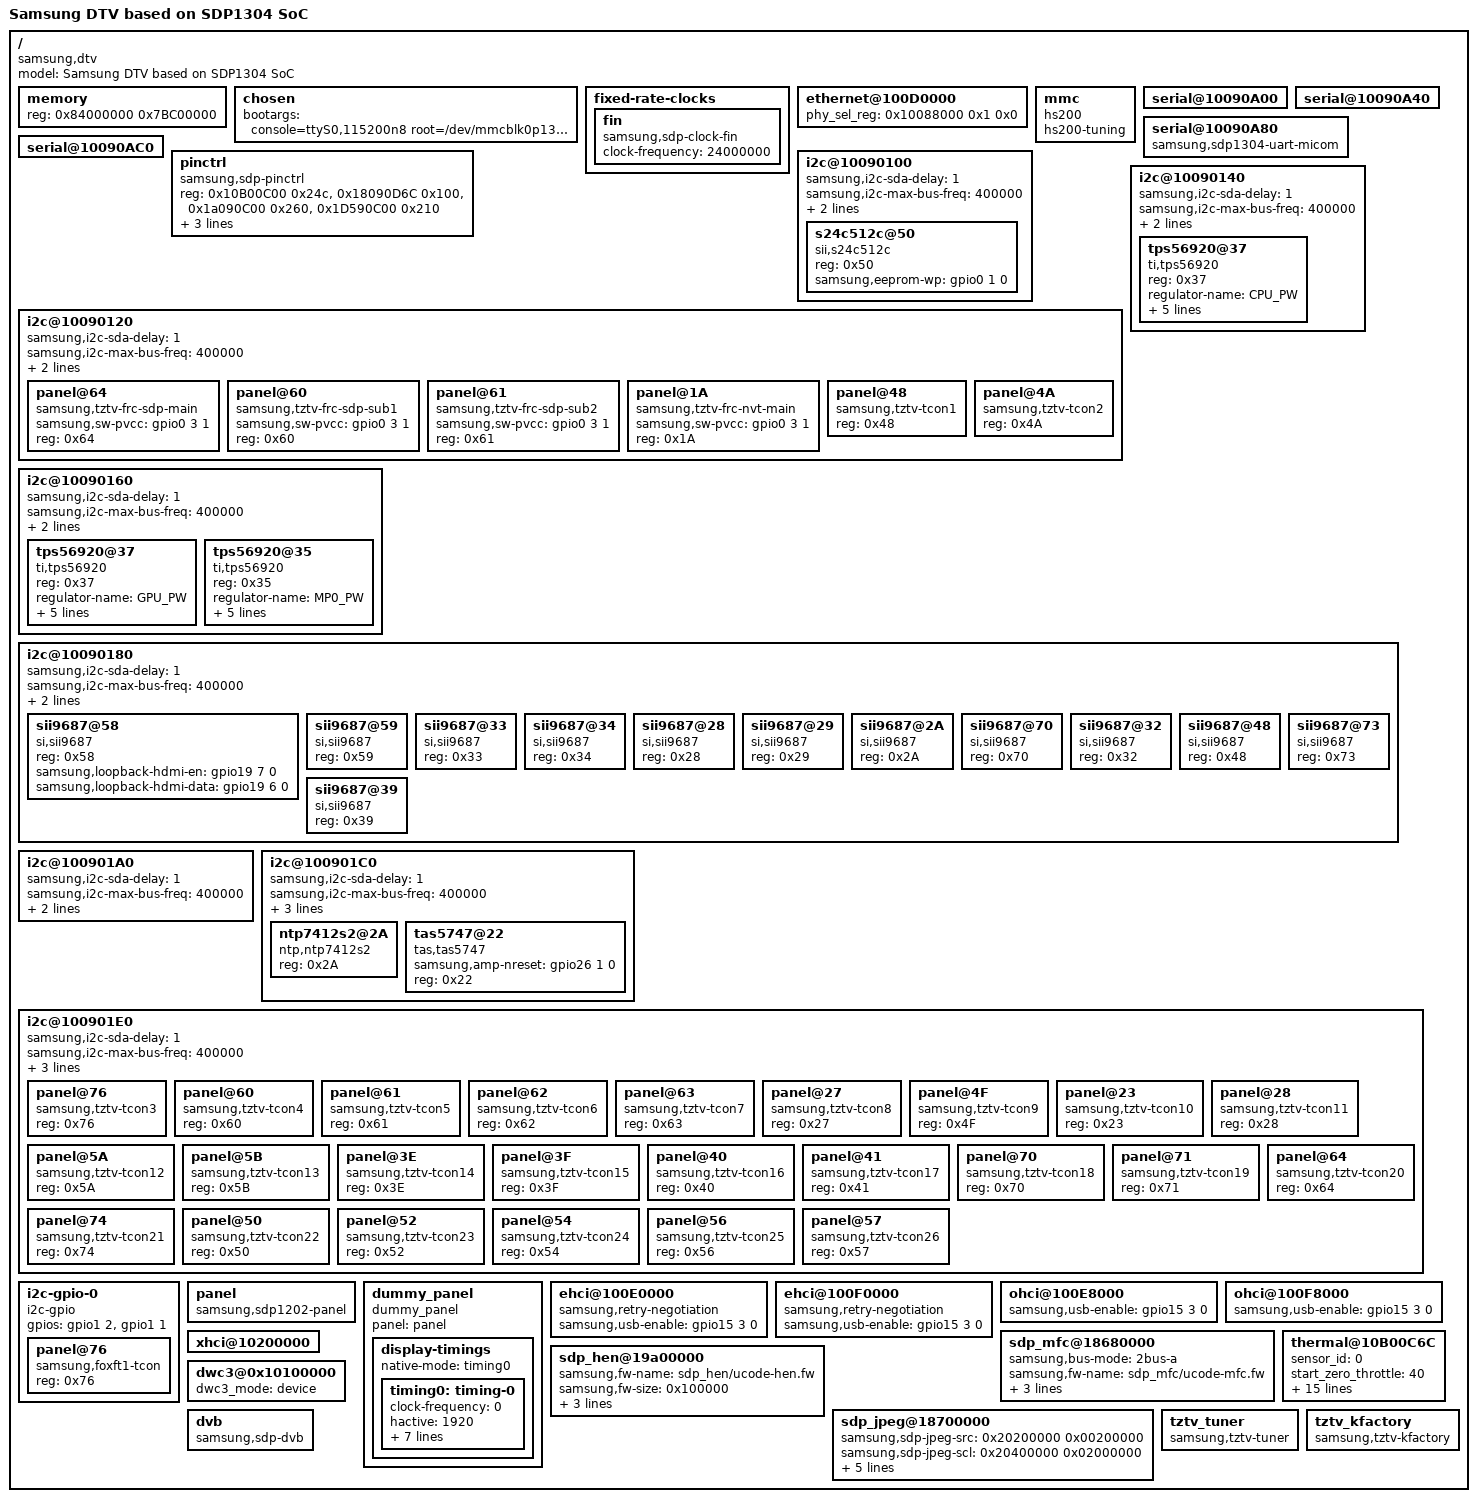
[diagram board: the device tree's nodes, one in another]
/*
 * Copyright (C) 2013 Samsung Electronics Co.Ltd
 *
 * This program is free software; you can redistribute it and/or modify
 * it under the terms of the GNU General Public License version 2 as
 * published by the Free Software Foundation.
 */

/dts-v1/;
#include "sdp1304.dtsi"

/ {
	model = "Samsung DTV based on SDP1304 SoC";
	compatible = "samsung,dtv", "samsung,sdp1304";

        memory {
                reg =  <0x84000000 0x7BC00000>;
        };

        chosen {
                bootargs = "console=ttyS0,115200n8 root=/dev/mmcblk0p13 rootfstype=ext4 rw rootwait earlyprintk no_console_suspend EME_BUFFINFO=0x83F00000,256K vmalloc=400M maintv sdp_sparsemem";
        };

	fixed-rate-clocks {
		fin {
			compatible = "samsung,sdp-clock-fin";
			clock-frequency = <24000000>;
		};
	};

	ethernet@100D0000 {
		phy_sel_reg = <0x10088000 0x1 0x0>;		/* select RGMII for eval board*/
	};

	mmc {
		hs200;/* enable HS200 */
		hs200-tuning;
	};

	serial@10090A00 {
		status = "okay";
	};

	serial@10090A40 {
		status = "okay";
	};

	serial@10090A80 {
		compatible = "samsung,sdp1304-uart-micom";
		status = "okay";
	};

	serial@10090AC0 {
		status = "okay";
	}; 

	pinctrl{
		compatible = "samsung,sdp-pinctrl";
		reg = <0x10B00C00 0x24c>,
			<0x18090D6C 0x100>,
			 <0x1a090C00 0x260>,
			 <0x1D590C00 0x210>;
			 
		start-offset = <0x98 0x0 0x16c 0x1a4>;
		nr-banks = <15 20 20 6>;	
		model-sel = <1 1 0 0>;	
	};

	i2c@10090100 {
		status = "okay";
		samsung,i2c-sda-delay = <1>;
		samsung,i2c-max-bus-freq = <400000>;
		samsung,i2c-irq-status-reg = <0x100901F4>;
		samsung,i2c-cpu-affinity = <3>;

                s24c512c@50 {
			compatible = "sii,s24c512c";
			reg = <0x50>;
			samsung,eeprom-wp = <&gpio0 1 0>;
                };
	};

	i2c@10090120 {
		status = "okay";
		samsung,i2c-sda-delay = <1>;
		samsung,i2c-max-bus-freq = <400000>;
		samsung,i2c-irq-status-reg = <0x100901F4>;
		samsung,i2c-cpu-affinity = <3>;

		/* panel C8 */
		panel@64 {
			compatible = "samsung,tztv-frc-sdp-main";
			samsung,sw-pvcc = <&gpio0 3 1>;
			reg = <0x64>;
		};

		/* panel C0 SUB */
		panel@60 {
			compatible = "samsung,tztv-frc-sdp-sub1";
			samsung,sw-pvcc = <&gpio0 3 1>;
			reg = <0x60>;
		};

		/* panel C2 SUB */
		panel@61 {
			compatible = "samsung,tztv-frc-sdp-sub2";
			samsung,sw-pvcc = <&gpio0 3 1>;
			 reg = <0x61>;
		};

		/* panel 34 */
		panel@1A {
			compatible = "samsung,tztv-frc-nvt-main";
			samsung,sw-pvcc = <&gpio0 3 1>;
			 reg = <0x1A>;
		};

		/* panel 0x90 */
		panel@48 {
			compatible = "samsung,tztv-tcon1";
			reg = <0x48>;
		};

		/* panel 0x94 */
		panel@4A {
			compatible = "samsung,tztv-tcon2";
			reg = <0x4A>;
		};
	};

	i2c@10090140 { 
		status = "okay";
		samsung,i2c-sda-delay = <1>;
		samsung,i2c-max-bus-freq = <400000>;
		samsung,i2c-irq-status-reg = <0x100901F4>;
		samsung,i2c-cpu-affinity = <3>;

		tps56920@37 {
			compatible = "ti,tps56920";
			reg = <0x37>;

			regulator-name = "CPU_PW";
			regulator-min-microvolt = <600000>;
			regulator-max-microvolt = <1870000>;
			regulator-always-on;
			regulator-boot-on;

			default_volt = <1270000>;
		};
	};

	i2c@10090160 {
		status = "okay";
		samsung,i2c-sda-delay = <1>;
		samsung,i2c-max-bus-freq = <400000>;
		samsung,i2c-irq-status-reg = <0x100901F4>;
		samsung,i2c-cpu-affinity = <3>;

		tps56920@37 {
			compatible = "ti,tps56920";
			reg = <0x37>;

			regulator-name = "GPU_PW";
			regulator-min-microvolt = <600000>;
			regulator-max-microvolt = <1870000>;
			regulator-always-on;
			regulator-boot-on;
			
			default_volt = <1100000>;
		};
		
		tps56920@35 {
			compatible = "ti,tps56920";
			reg = <0x35>;

			regulator-name = "MP0_PW";
			regulator-min-microvolt = <600000>;
			regulator-max-microvolt = <1870000>;
			regulator-always-on;
			regulator-boot-on;

			default_volt = <1200000>;
		};

/*
		tps56920@36 {
			compatible = "ti,tps56920";
			reg = <0x36>;

			regulator-name = "MP1_PW";
			regulator-min-microvolt = <600000>;
			regulator-max-microvolt = <1870000>;
			regulator-always-on;
			regulator-boot-on;

			default_volt = <1100000>;
		};
*/
	};

	i2c@10090180 {
		status = "okay";
		samsung,i2c-sda-delay = <1>;
		samsung,i2c-max-bus-freq = <400000>;
		samsung,i2c-irq-status-reg = <0x100901F4>;
		samsung,i2c-cpu-affinity = <3>;

		/* sii9687 0xB0*/
		sii9687@58 {
			compatible = "si,sii9687";
			reg = <0x58>;			
			samsung,loopback-hdmi-en = <&gpio19 7 0>;
			samsung,loopback-hdmi-data = <&gpio19 6 0>;			
		};
		/* sii9687 0xB2*/
		sii9687@59 {
			compatible = "si,sii9687";
			reg = <0x59>;						
		};
				
		/*sii9687 0x66*/
		sii9687@33 {
			compatible = "si,sii9687";
			reg = <0x33>;			
		};
		
		/*sii9687  0x68*/
		sii9687@34 {
			compatible = "si,sii9687";
			reg = <0x34>;			
		};
		/*sii9687  0x50*/
		sii9687@28 {
			compatible = "si,sii9687";
			reg = <0x28>;			
		};
		/*sii9687  0x52*/
		sii9687@29 {
			compatible = "si,sii9687";
			reg = <0x29>;			
		};
		/*sii9687  0x54*/
		sii9687@2A {
			compatible = "si,sii9687";
			reg = <0x2A>;			
		};
		/*sii9687  0xE0*/
		sii9687@70 {
			compatible = "si,sii9687";
			reg = <0x70>;			
		};
		/*sii9687  0x64*/
		sii9687@32 {
			compatible = "si,sii9687";
			reg = <0x32>;			
		};
		/*sii9687  0x90*/
		sii9687@48 {
			compatible = "si,sii9687";
			reg = <0x48>;			
		};
		/*sii9687  0xE6*/
		sii9687@73 {
			compatible = "si,sii9687";
			reg = <0x73>;			
		};
		/*sii9687  0x72*/
		sii9687@39 {
			compatible = "si,sii9687";
			reg = <0x39>;			
		};
	};

	i2c@100901A0 {
		status = "okay";
		samsung,i2c-sda-delay = <1>;
		samsung,i2c-max-bus-freq = <400000>;
		samsung,i2c-irq-status-reg = <0x100901F4>;
		samsung,i2c-cpu-affinity = <3>;

	};

	i2c@100901C0 {
		status = "okay";
		samsung,i2c-sda-delay = <1>;
		samsung,i2c-max-bus-freq = <400000>;
		samsung,i2c-irq-status-reg = <0x100901F4>;
		samsung,i2c-pad-enable = <0x10B00C40 0x8000>;
		samsung,i2c-cpu-affinity = <3>;
		
		ntp7412s2@2A {
			compatible = "ntp,ntp7412s2";              
			reg = <0x2A>;
		};
		
		tas5747@22 {
			compatible = "tas,tas5747";              
			samsung,amp-nreset = <&gpio26 1 0>;              
			reg = <0x22>;
		};
	};

	i2c@100901E0 {
		status = "okay";
		samsung,i2c-sda-delay = <1>;
		samsung,i2c-max-bus-freq = <400000>;
		samsung,i2c-irq-status-reg = <0x100901F4>;
		samsung,i2c-pad-enable = <0x10B00C40 0x10000>;
		samsung,i2c-cpu-affinity = <3>;

		/* panel 0xEC */
		panel@76 {
			compatible = "samsung,tztv-tcon3";
			reg = <0x76>;
		};

		/* panel 0xC0 */
		panel@60 {
			compatible = "samsung,tztv-tcon4";
			reg = <0x60>;
		};

		/* panel 0xC2 */
		panel@61 {
			compatible = "samsung,tztv-tcon5";
			reg = <0x61>;
		};

		/* panel 0xC4 */
		panel@62 {
			compatible = "samsung,tztv-tcon6";
			reg = <0x62>;
		};

		/* panel 0xC6 */
		panel@63 {
			compatible = "samsung,tztv-tcon7";
			reg = <0x63>;
		};

		/* panel 0x4E */
		panel@27 {
			compatible = "samsung,tztv-tcon8";
			reg = <0x27>;
		};

		/* panel 0x9E */
		panel@4F {
			compatible = "samsung,tztv-tcon9";
			reg = <0x4F>;
		};

		/* panel 0x46 */
		panel@23 {
			compatible = "samsung,tztv-tcon10";
			reg = <0x23>;
		};

		/* panel 0x50 */
		panel@28 {
			compatible = "samsung,tztv-tcon11";
			reg = <0x28>;
		};

		/* panel 0xB4 */
		panel@5A {
			compatible = "samsung,tztv-tcon12";
			reg = <0x5A>;
		};

		/* panel 0xB6 */
		panel@5B {
			compatible = "samsung,tztv-tcon13";
			reg = <0x5B>;
		};

		/* panel 0x7C */
		panel@3E {
			compatible = "samsung,tztv-tcon14";
			reg = <0x3E>;
		};

		/* panel 0x7E */
		panel@3F {
			compatible = "samsung,tztv-tcon15";
			reg = <0x3F>;
		};

		/* panel 0x80 */
		panel@40 {
			compatible = "samsung,tztv-tcon16";
			reg = <0x40>;
		};

		/* panel 0x82 */
		panel@41 {
			compatible = "samsung,tztv-tcon17";
			reg = <0x41>;
		};

		/* panel 0xE0 */
		panel@70 {
			compatible = "samsung,tztv-tcon18";
			reg = <0x70>;
		};

		/* panel 0xE2 */
		panel@71 {
			compatible = "samsung,tztv-tcon19";
			reg = <0x71>;
		};

		/* panel 0xC8 */
		panel@64 {
			compatible = "samsung,tztv-tcon20";
			reg = <0x64>;
		};

		/* panel 0xE8 */
		panel@74 {
			compatible = "samsung,tztv-tcon21";
			reg = <0x74>;
		};

		/* panel 0xA0 */
		panel@50 {
			compatible = "samsung,tztv-tcon22";
			reg = <0x50>;
		};

		/* panel 0xA4 */
		panel@52 {
			compatible = "samsung,tztv-tcon23";
			reg = <0x52>;
		};

		/* panel 0xA8 */
		panel@54 {
			compatible = "samsung,tztv-tcon24";
			reg = <0x54>;
		};

		/* panel 0xAC */
		panel@56 {
			compatible = "samsung,tztv-tcon25";
			reg = <0x56>;
		};

		/* panel 0xAE */
		panel@57 {
			compatible = "samsung,tztv-tcon26";
			reg = <0x57>;
		};
	};

	i2c-gpio-0 {
		compatible = "i2c-gpio";
		gpios = <&gpio1 2 0>, <&gpio1 1 0>;
		#address-cells = <1>;
		#size-cells = <0>;

		panel@76 {
			compatible = "samsung,foxft1-tcon";
			reg = <0x76>;
		};
	};

	panel: panel {
		compatible = "samsung,sdp1202-panel";

	};

	dummy_panel {
		compatible = "dummy_panel";

		panel = <&panel>;

		display-timings {
			native-mode = <&timing0>;

			timing0: timing-0 {
				 clock-frequency = <0>;
				 hactive = <1920>;
				 vactive = <1080>;
				 hfront-porch = <0>;
				 hback-porch = <0>;
				 hsync-len = <0>;
				 vfront-porch = <0>;
				 vback-porch = <0>;
				 vsync-len = <0>;
			};
		};
	};

	ehci@100E0000 {
		status = "okay";
		samsung,retry-negotiation;
	/*
		samsung,sw-reset = <0x10B00000 0x954 0x1>;
		samsung,ehci-gpr_reg = <0x100FC000 0x00 0xE05A>;
		samsung,ehci-gpr_reg1 = <0x100FC000 0x04 0x5000>;
		samsung,sw-reset-release = <0x10B00000 0x954 0x1>;
	*/
		samsung,usb-enable = <&gpio15 3 0>;
	};

	ehci@100F0000 {
		status = "okay";
		samsung,retry-negotiation;
	/*
		samsung,sw-reset = <0x10B00000 0x954 0x2>;
		samsung,ehci-gpr_reg = <0x100FC000 0x14 0xE05A>;
		samsung,ehci-gpr_reg1 = <0x100FC000 0x18 0x5000>;
		samsung,sw-reset-release = <0x10B00000 0x954 0x2>;
	*/
		samsung,usb-enable = <&gpio15 3 0>;
	};

	ohci@100E8000 {
		status = "okay";
		samsung,usb-enable = <&gpio15 3 0>;
	};

	ohci@100F8000 {
		status = "okay";
		samsung,usb-enable = <&gpio15 3 0>;
	};

	sdp_mfc@18680000 {
		samsung,bus-mode = "2bus-a";
		samsung,fw-name = "sdp_mfc/ucode-mfc.fw";
		samsung,fw-size = <0x60000>;
		/*
		 * FIXME
		 * maybe these addresses are configurable.
		 * if so, please remove them.
		 */
 		samsung,dram-base-a = <0x20000000>;
		samsung,dram-base-b = <0x30000000>;
	};

sdp_hen@19a00000 {
		samsung,fw-name = "sdp_hen/ucode-hen.fw";
		samsung,fw-size = <0x100000>;
		samsung,dram-base-a = <0x24100000>;
		samsung,dram-base-b = <0x31600000>;
		samsung,src-base = <0x31880000>;
};	

        sdp_jpeg@18700000 {
                samsung,sdp-jpeg-src = <0x20200000 0x00200000>;
                samsung,sdp-jpeg-scl = <0x20400000 0x02000000>;
                samsung,sdp-jpeg-dst = <0x22400000 0x00880000>;
                samsung,sdp-jpeg-mjpeg-y = <0x33D00000 0x340F5000 0x344EA000 0x348DF000 0x367C0000>;
                samsung,sdp-jpeg-mjpeg-c = <0x24C80000 0x25469000 0x25C52000 0x2643B000 0x2709EB85>;
        };

	xhci@10200000 {
		status = "okay";
	};

	thermal@10B00C6C {
		status = "okay";

		sensor_id = <0>;

		start_zero_throttle	= <40>;
		stop_zero_throttle	= <45>;
		stop_1st_throttle	= <102>;
		start_1st_throttle	= <110>;
		stop_2nd_throttle	= <112>;
		start_2nd_throttle	= <118>;
		stop_3rd_throttle	= <120>;
		start_3rd_throttle	= <125>;
		start_3rd_hotplug	= <130>;

		cpu_limit_1st_throttle	= <1000000>;
		cpu_limit_2nd_throttle	= <600000>;
		cpu_limit_3rd_throttle	= <100000>;

		gpu_limit_1st_throttle	= <200000>;
		gpu_limit_2nd_throttle	= <200000>;
		gpu_limit_3rd_throttle	= <50000>;

		log_file_path = "/mtd_rwarea/ThermalThrottle.txt";
	};
	
	dwc3@0x10100000 {
		status = "okay";
		dwc3_mode = "device";
	};
	
	dvb {
		compatible = "samsung,sdp-dvb";
	};

	tztv_tuner {
		compatible = "samsung,tztv-tuner";
	};
	
	tztv_kfactory {
		compatible = "samsung,tztv-kfactory";
	};
};
